VERSION "Body_CAN_v1.0"

NS_ :

BS_:

BU_: BODY_GW BCM_AMBIENT_CTRL HAZARD_CTRL WINDOW_CTRL DRIVER_STATE_CTRL WARN_ARB_MGR DOMAIN_BOUNDARY_MGR VAL_SCENARIO_CTRL Vector__XXX

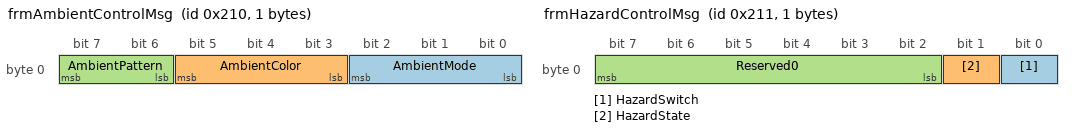
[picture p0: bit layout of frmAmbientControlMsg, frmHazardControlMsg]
BO_ 528 frmAmbientControlMsg: 1 BODY_GW
 SG_ AmbientMode    : 0|3@1+ (1,0) [0|7] "" BCM_AMBIENT_CTRL
 SG_ AmbientColor   : 3|3@1+ (1,0) [0|7] "" BCM_AMBIENT_CTRL
 SG_ AmbientPattern : 6|2@1+ (1,0) [0|3] "" BCM_AMBIENT_CTRL

BO_ 529 frmHazardControlMsg: 1 BODY_GW
 SG_ HazardSwitch     : 0|1@1+ (1,0) [0|1] "" HAZARD_CTRL
 SG_ HazardState      : 1|1@1+ (1,0) [0|1] "" HAZARD_CTRL
 SG_ Reserved0        : 2|6@1+ (1,0) [0|0] "" Vector__XXX

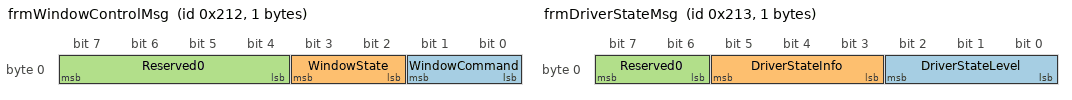
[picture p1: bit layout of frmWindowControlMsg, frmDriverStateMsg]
BO_ 530 frmWindowControlMsg: 1 BODY_GW
 SG_ WindowCommand    : 0|2@1+ (1,0) [0|3] "" WINDOW_CTRL
 SG_ WindowState      : 2|2@1+ (1,0) [0|3] "" WINDOW_CTRL
 SG_ Reserved0        : 4|4@1+ (1,0) [0|0] "" Vector__XXX

BO_ 531 frmDriverStateMsg: 1 BODY_GW
 SG_ DriverStateLevel : 0|3@1+ (1,0) [0|7] "" DRIVER_STATE_CTRL
 SG_ DriverStateInfo  : 3|3@1+ (1,0) [0|7] "" DRIVER_STATE_CTRL
 SG_ Reserved0        : 6|2@1+ (1,0) [0|0] "" Vector__XXX

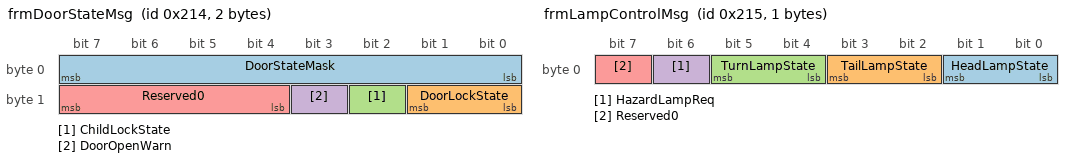
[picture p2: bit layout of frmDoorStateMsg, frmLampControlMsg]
BO_ 532 frmDoorStateMsg: 2 BODY_GW
 SG_ DoorStateMask    : 0|8@1+ (1,0) [0|255] "" WINDOW_CTRL,DRIVER_STATE_CTRL
 SG_ DoorLockState    : 8|2@1+ (1,0) [0|3] "" WINDOW_CTRL,DRIVER_STATE_CTRL
 SG_ ChildLockState   : 10|1@1+ (1,0) [0|1] "" WINDOW_CTRL,DRIVER_STATE_CTRL
 SG_ DoorOpenWarn     : 11|1@1+ (1,0) [0|1] "" WINDOW_CTRL,DRIVER_STATE_CTRL
 SG_ Reserved0        : 12|4@1+ (1,0) [0|0] "" Vector__XXX

BO_ 533 frmLampControlMsg: 1 BODY_GW
 SG_ HeadLampState    : 0|2@1+ (1,0) [0|3] "" BCM_AMBIENT_CTRL
 SG_ TailLampState    : 2|2@1+ (1,0) [0|3] "" BCM_AMBIENT_CTRL
 SG_ TurnLampState    : 4|2@1+ (1,0) [0|3] "" BCM_AMBIENT_CTRL
 SG_ HazardLampReq    : 6|1@1+ (1,0) [0|1] "" HAZARD_CTRL
 SG_ Reserved0        : 7|1@1+ (1,0) [0|0] "" Vector__XXX

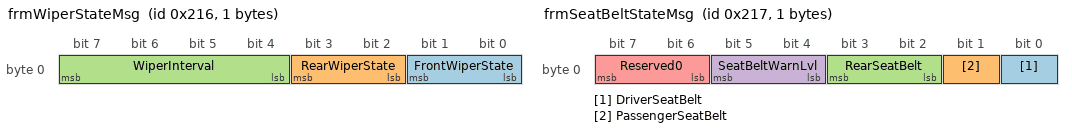
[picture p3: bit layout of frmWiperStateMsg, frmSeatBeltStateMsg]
BO_ 534 frmWiperStateMsg: 1 BODY_GW
 SG_ FrontWiperState  : 0|2@1+ (1,0) [0|3] "" BCM_AMBIENT_CTRL
 SG_ RearWiperState   : 2|2@1+ (1,0) [0|3] "" BCM_AMBIENT_CTRL
 SG_ WiperInterval    : 4|4@1+ (1,0) [0|15] "" BCM_AMBIENT_CTRL

BO_ 535 frmSeatBeltStateMsg: 1 DRIVER_STATE_CTRL
 SG_ DriverSeatBelt   : 0|1@1+ (1,0) [0|1] "" BODY_GW,BCM_AMBIENT_CTRL
 SG_ PassengerSeatBelt : 1|1@1+ (1,0) [0|1] "" BODY_GW,BCM_AMBIENT_CTRL
 SG_ RearSeatBelt     : 2|2@1+ (1,0) [0|3] "" BODY_GW,BCM_AMBIENT_CTRL
 SG_ SeatBeltWarnLvl  : 4|2@1+ (1,0) [0|3] "" BODY_GW,BCM_AMBIENT_CTRL
 SG_ Reserved0        : 6|2@1+ (1,0) [0|0] "" Vector__XXX

BO_ 536 frmCabinAirStateMsg: 2 DRIVER_STATE_CTRL
 SG_ CabinTemp        : 0|8@1+ (1,0) [0|100] "degC" BODY_GW
 SG_ AirQualityIndex  : 8|8@1+ (1,0) [0|255] "" BODY_GW

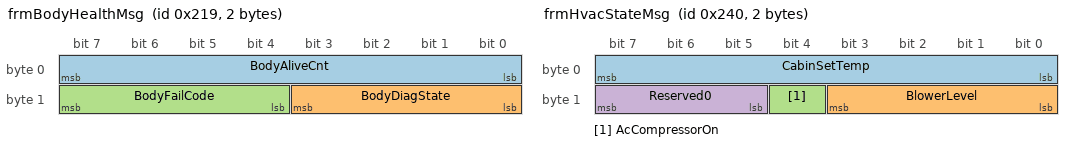
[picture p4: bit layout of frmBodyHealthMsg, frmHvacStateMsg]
BO_ 537 frmBodyHealthMsg: 2 BODY_GW
 SG_ BodyAliveCnt     : 0|8@1+ (1,0) [0|255] "" VAL_SCENARIO_CTRL,DOMAIN_BOUNDARY_MGR
 SG_ BodyDiagState    : 8|4@1+ (1,0) [0|15] "" VAL_SCENARIO_CTRL,DOMAIN_BOUNDARY_MGR
 SG_ BodyFailCode     : 12|4@1+ (1,0) [0|15] "" VAL_SCENARIO_CTRL,DOMAIN_BOUNDARY_MGR

BO_ 576 frmHvacStateMsg: 2 BODY_GW
 SG_ CabinSetTemp     : 0|8@1+ (1,0) [0|100] "degC" DRIVER_STATE_CTRL
 SG_ BlowerLevel      : 8|4@1+ (1,0) [0|15] "" DRIVER_STATE_CTRL
 SG_ AcCompressorOn   : 12|1@1+ (1,0) [0|1] "" DRIVER_STATE_CTRL
 SG_ Reserved0        : 13|3@1+ (1,0) [0|0] "" Vector__XXX

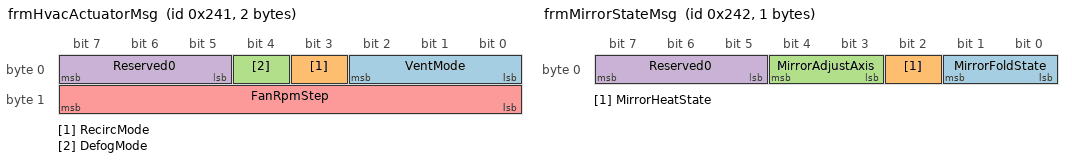
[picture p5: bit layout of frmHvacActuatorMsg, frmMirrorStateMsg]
BO_ 577 frmHvacActuatorMsg: 2 BODY_GW
 SG_ VentMode         : 0|3@1+ (1,0) [0|7] "" DRIVER_STATE_CTRL
 SG_ RecircMode       : 3|1@1+ (1,0) [0|1] "" DRIVER_STATE_CTRL
 SG_ DefogMode        : 4|1@1+ (1,0) [0|1] "" DRIVER_STATE_CTRL
 SG_ Reserved0        : 5|3@1+ (1,0) [0|0] "" Vector__XXX
 SG_ FanRpmStep       : 8|8@1+ (1,0) [0|255] "" DRIVER_STATE_CTRL

BO_ 578 frmMirrorStateMsg: 1 BODY_GW
 SG_ MirrorFoldState  : 0|2@1+ (1,0) [0|3] "" WINDOW_CTRL
 SG_ MirrorHeatState  : 2|1@1+ (1,0) [0|1] "" WINDOW_CTRL
 SG_ MirrorAdjustAxis : 3|2@1+ (1,0) [0|3] "" WINDOW_CTRL
 SG_ Reserved0        : 5|3@1+ (1,0) [0|0] "" Vector__XXX

BO_ 579 frmSeatStateMsg: 2 DRIVER_STATE_CTRL
 SG_ DriverSeatPos    : 0|8@1+ (1,0) [0|255] "" BODY_GW
 SG_ PassengerSeatPos : 8|8@1+ (1,0) [0|255] "" BODY_GW

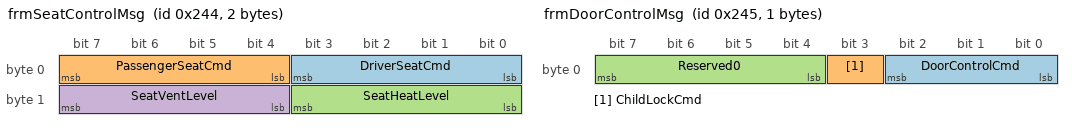
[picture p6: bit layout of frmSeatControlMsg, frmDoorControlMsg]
BO_ 580 frmSeatControlMsg: 2 DRIVER_STATE_CTRL
 SG_ DriverSeatCmd    : 0|4@1+ (1,0) [0|15] "" BODY_GW
 SG_ PassengerSeatCmd : 4|4@1+ (1,0) [0|15] "" BODY_GW
 SG_ SeatHeatLevel    : 8|4@1+ (1,0) [0|15] "" BODY_GW
 SG_ SeatVentLevel    : 12|4@1+ (1,0) [0|15] "" BODY_GW

BO_ 581 frmDoorControlMsg: 1 WINDOW_CTRL
 SG_ DoorControlCmd   : 0|3@1+ (1,0) [0|7] "" BODY_GW
 SG_ ChildLockCmd     : 3|1@1+ (1,0) [0|1] "" BODY_GW
 SG_ Reserved0        : 4|4@1+ (1,0) [0|0] "" Vector__XXX

BO_ 582 frmInteriorLightMsg: 1 BCM_AMBIENT_CTRL
 SG_ CabinLightMode   : 0|3@1+ (1,0) [0|7] "" BODY_GW
 SG_ DomeLightLevel   : 3|5@1+ (1,0) [0|31] "" BODY_GW

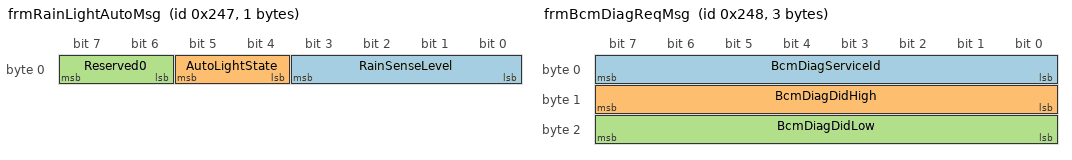
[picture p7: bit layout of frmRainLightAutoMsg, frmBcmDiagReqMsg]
BO_ 583 frmRainLightAutoMsg: 1 BCM_AMBIENT_CTRL
 SG_ RainSenseLevel   : 0|4@1+ (1,0) [0|15] "" BODY_GW
 SG_ AutoLightState   : 4|2@1+ (1,0) [0|3] "" BODY_GW
 SG_ Reserved0        : 6|2@1+ (1,0) [0|0] "" Vector__XXX

BO_ 584 frmBcmDiagReqMsg: 3 BODY_GW
 SG_ BcmDiagServiceId : 0|8@1+ (1,0) [0|255] "" BCM_AMBIENT_CTRL
 SG_ BcmDiagDidHigh   : 8|8@1+ (1,0) [0|255] "" BCM_AMBIENT_CTRL
 SG_ BcmDiagDidLow    : 16|8@1+ (1,0) [0|255] "" BCM_AMBIENT_CTRL

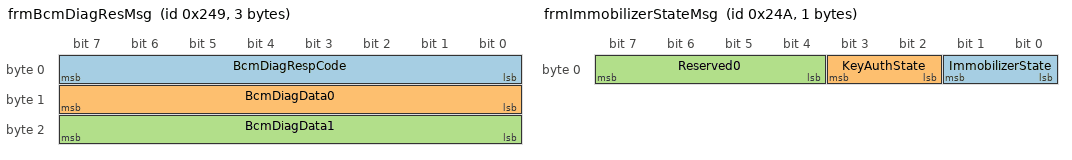
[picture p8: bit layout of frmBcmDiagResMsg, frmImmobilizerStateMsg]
BO_ 585 frmBcmDiagResMsg: 3 BCM_AMBIENT_CTRL
 SG_ BcmDiagRespCode  : 0|8@1+ (1,0) [0|255] "" BODY_GW
 SG_ BcmDiagData0     : 8|8@1+ (1,0) [0|255] "" BODY_GW
 SG_ BcmDiagData1     : 16|8@1+ (1,0) [0|255] "" BODY_GW

BO_ 586 frmImmobilizerStateMsg: 1 BODY_GW
 SG_ ImmobilizerState : 0|2@1+ (1,0) [0|3] "" DRIVER_STATE_CTRL
 SG_ KeyAuthState     : 2|2@1+ (1,0) [0|3] "" DRIVER_STATE_CTRL
 SG_ Reserved0        : 4|4@1+ (1,0) [0|0] "" Vector__XXX

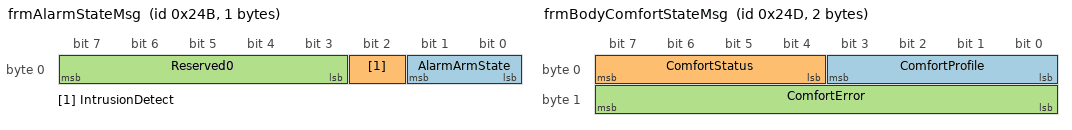
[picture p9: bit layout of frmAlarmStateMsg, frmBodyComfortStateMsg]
BO_ 587 frmAlarmStateMsg: 1 BODY_GW
 SG_ AlarmArmState    : 0|2@1+ (1,0) [0|3] "" DRIVER_STATE_CTRL
 SG_ IntrusionDetect  : 2|1@1+ (1,0) [0|1] "" DRIVER_STATE_CTRL
 SG_ Reserved0        : 3|5@1+ (1,0) [0|0] "" Vector__XXX

BO_ 588 frmBodyGatewayStateMsg: 2 BODY_GW
 SG_ BodyGwRouteState : 0|8@1+ (1,0) [0|255] "" WARN_ARB_MGR
 SG_ BodyGwHealth     : 8|8@1+ (1,0) [0|255] "" WARN_ARB_MGR

BO_ 589 frmBodyComfortStateMsg: 2 BODY_GW
 SG_ ComfortProfile   : 0|4@1+ (1,0) [0|15] "" WARN_ARB_MGR
 SG_ ComfortStatus    : 4|4@1+ (1,0) [0|15] "" WARN_ARB_MGR
 SG_ ComfortError     : 8|8@1+ (1,0) [0|255] "" WARN_ARB_MGR

CM_ BO_ 528 "Flow_007 ambient output.";
CM_ BO_ 529 "Body baseline: hazard switch and hazard state.";
CM_ BO_ 530 "Body baseline: window command and window state.";
CM_ BO_ 531 "Body baseline: driver state level and state info.";
CM_ BO_ 532 "Body baseline: door mask/lock/child-lock/open-warning state.";
CM_ BO_ 533 "Body baseline: lamp and hazard request state.";
CM_ BO_ 534 "Body baseline: front/rear wiper state and interval.";
CM_ BO_ 535 "Body baseline: seat-belt occupancy and warning level.";
CM_ BO_ 536 "Body baseline: cabin temperature and air quality index.";
CM_ BO_ 537 "Body health/diagnostic state.";
CM_ BO_ 576 "Comm_202: HVAC state extension.";
CM_ BO_ 577 "Comm_202: HVAC actuator extension.";
CM_ BO_ 578 "Comm_202: mirror state extension.";
CM_ BO_ 579 "Comm_202: seat state extension.";
CM_ BO_ 580 "Comm_202: seat control extension.";
CM_ BO_ 581 "Comm_202: door control extension.";
CM_ BO_ 582 "Comm_202: interior light extension.";
CM_ BO_ 583 "Comm_202: rain/light auto extension.";
CM_ BO_ 584 "Comm_202: BCM diagnostic request.";
CM_ BO_ 585 "Comm_202: BCM diagnostic response.";
CM_ BO_ 586 "Comm_202: immobilizer state extension.";
CM_ BO_ 587 "Comm_202: alarm state extension.";
CM_ BO_ 588 "Comm_202: body gateway status extension.";
CM_ BO_ 589 "Comm_202: body comfort status extension.";

BA_DEF_ BO_ "GenMsgCycleTime" INT 0 10000;
BA_DEF_DEF_ "GenMsgCycleTime" 0;
BA_ "GenMsgCycleTime" BO_ 528 50;
BA_ "GenMsgCycleTime" BO_ 529 100;
BA_ "GenMsgCycleTime" BO_ 530 100;
BA_ "GenMsgCycleTime" BO_ 531 100;
BA_ "GenMsgCycleTime" BO_ 532 100;
BA_ "GenMsgCycleTime" BO_ 533 100;
BA_ "GenMsgCycleTime" BO_ 534 100;
BA_ "GenMsgCycleTime" BO_ 535 100;
BA_ "GenMsgCycleTime" BO_ 536 100;
BA_ "GenMsgCycleTime" BO_ 537 100;
BA_ "GenMsgCycleTime" BO_ 576 100;
BA_ "GenMsgCycleTime" BO_ 577 100;
BA_ "GenMsgCycleTime" BO_ 578 100;
BA_ "GenMsgCycleTime" BO_ 579 100;
BA_ "GenMsgCycleTime" BO_ 580 100;
BA_ "GenMsgCycleTime" BO_ 581 100;
BA_ "GenMsgCycleTime" BO_ 582 100;
BA_ "GenMsgCycleTime" BO_ 583 100;
BA_ "GenMsgCycleTime" BO_ 586 100;
BA_ "GenMsgCycleTime" BO_ 587 100;
BA_ "GenMsgCycleTime" BO_ 588 100;
BA_ "GenMsgCycleTime" BO_ 589 100;

  0 "Off"
  1 "Basic"
  2 "Caution"
  3 "SchoolZone"
  4 "Reserved"
  5 "GuideLeft"
  6 "GuideRight"
  7 "Emergency" ;

  0 "Off"
  1 "On" ;

  0 "Inactive"
  1 "Active" ;

  0 "NoCmd"
  1 "Open"
  2 "Close"
  3 "Stop" ;

  0 "Unknown"
  1 "Opened"
  2 "Closed"
  3 "Moving" ;

  0 "Normal"
  1 "MildDrowsy"
  2 "Drowsy"
  3 "Distracted"
  4 "Critical"
  5 "Reserved5"
  6 "Reserved6"
  7 "Reserved7" ;

  0 "Unlocked"
  1 "Locked"
  2 "AutoLock"
  3 "Fault" ;

  0 "Off"
  1 "On" ;

  0 "NoWarn"
  1 "Warn" ;

  0 "Off"
  1 "Parking"
  2 "LowBeam"
  3 "HighBeam" ;

  0 "Off"
  1 "On"
  2 "Auto"
  3 "Fault" ;

  0 "Off"
  1 "Left"
  2 "Right"
  3 "Hazard" ;

  0 "Off"
  1 "On" ;

  0 "Off"
  1 "Low"
  2 "High"
  3 "Auto" ;

  0 "Off"
  1 "On"
  2 "Intermittent"
  3 "Fault" ;

  0 "Unbuckled"
  1 "Buckled" ;

  0 "Unbuckled"
  1 "Buckled" ;

  0 "None"
  1 "SomeUnbuckled"
  2 "AllBuckled"
  3 "Fault" ;

  0 "None"
  1 "Info"
  2 "Warn"
  3 "Critical" ;
